AUTOSAR XML (schema 4-0-3)
package /ComponentTypes
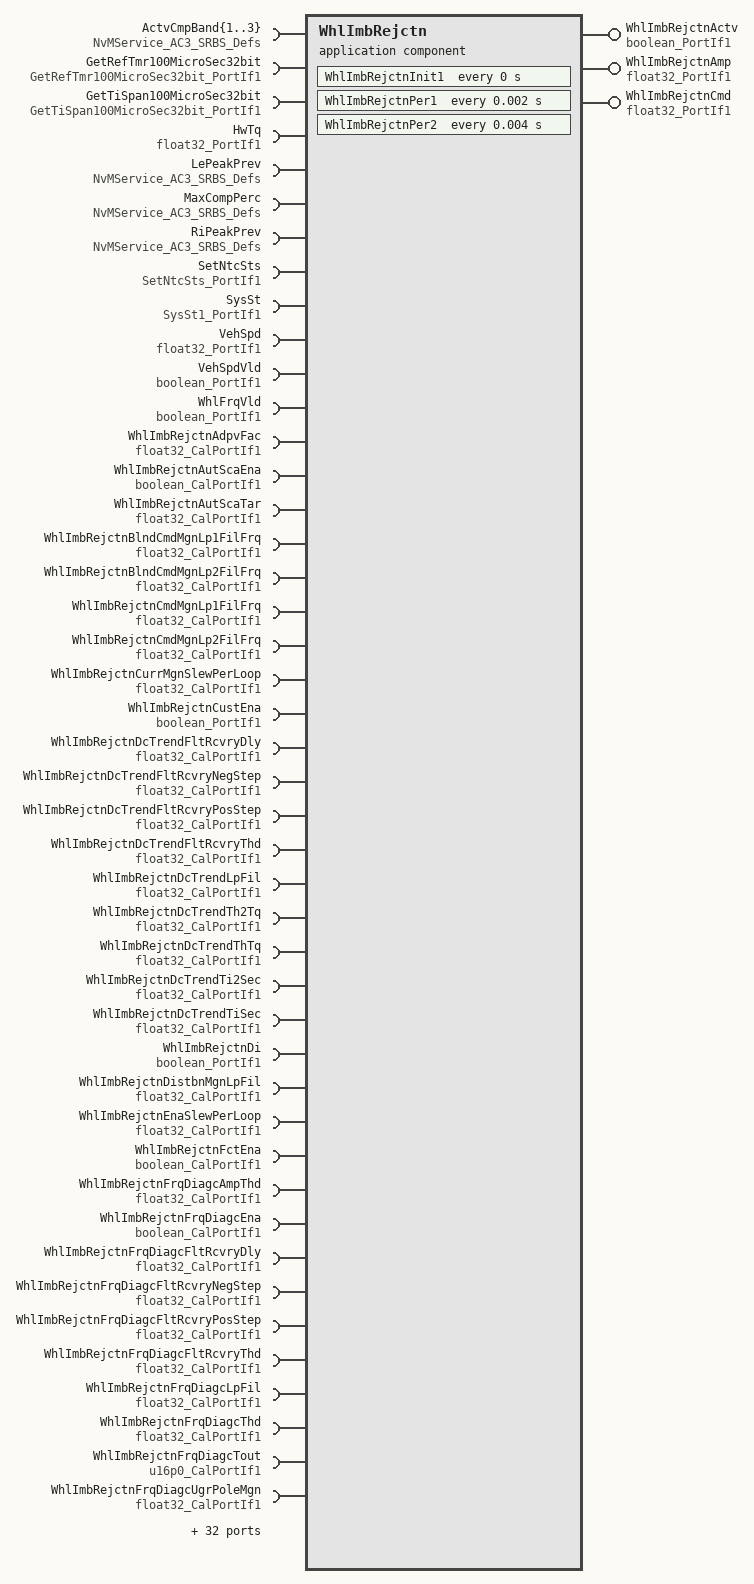
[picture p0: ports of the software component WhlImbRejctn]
  application sw component type WhlImbRejctn
    provide port WhlImbRejctnActv: nonqueued-sender-com-spec{data-element=Logl, init-value=0}, provided-interface=boolean_PortIf1
    provide port WhlImbRejctnAmp: nonqueued-sender-com-spec{data-element=Val, init-value=0}, provided-interface=float32_PortIf1
    provide port WhlImbRejctnCmd: nonqueued-sender-com-spec{data-element=Val, init-value=0}, provided-interface=float32_PortIf1
    78 x require port:
      ActvCmpBand{1..3}: required-interface=NvMService_AC3_SRBS_Defs
      GetRefTmr100MicroSec32bit: required-interface=GetRefTmr100MicroSec32bit_PortIf1
      GetTiSpan100MicroSec32bit: required-interface=GetTiSpan100MicroSec32bit_PortIf1
      HwTq: nonqueued-receiver-com-spec{data-element=Val, filter=data-filter-type=ALWAYS, init-value=0}, required-interface=float32_PortIf1
      LePeakPrev: required-interface=NvMService_AC3_SRBS_Defs
      MaxCompPerc: required-interface=NvMService_AC3_SRBS_Defs
      RiPeakPrev: required-interface=NvMService_AC3_SRBS_Defs
      SetNtcSts: required-interface=SetNtcSts_PortIf1
      SysSt: nonqueued-receiver-com-spec{data-element=Val, filter=data-filter-type=ALWAYS, init-value=3}, required-interface=SysSt1_PortIf1
      VehSpd: nonqueued-receiver-com-spec{data-element=Val, filter=data-filter-type=ALWAYS, init-value=0}, required-interface=float32_PortIf1
      VehSpdVld: nonqueued-receiver-com-spec{data-element=Logl, filter=data-filter-type=ALWAYS, init-value=1}, required-interface=boolean_PortIf1
      WhlFrqVld: nonqueued-receiver-com-spec{data-element=Logl, filter=data-filter-type=ALWAYS, init-value=0}, required-interface=boolean_PortIf1
      WhlImbRejctnAdpvFac: parameter-require-com-spec{init-value=0.199997, parameter=Val}, required-interface=float32_CalPortIf1
      WhlImbRejctnAutScaEna: parameter-require-com-spec{init-value=1, parameter=Logl}, required-interface=boolean_CalPortIf1
      WhlImbRejctnAutScaTar: parameter-require-com-spec{init-value=0.199219, parameter=Val}, required-interface=float32_CalPortIf1
      WhlImbRejctnBlndCmdMgnLp1FilFrq: parameter-require-com-spec{init-value=5, parameter=Val}, required-interface=float32_CalPortIf1
      WhlImbRejctnBlndCmdMgnLp2FilFrq: parameter-require-com-spec{init-value=5, parameter=Val}, required-interface=float32_CalPortIf1
      WhlImbRejctnCmdMgnLp1FilFrq: parameter-require-com-spec{init-value=5, parameter=Val}, required-interface=float32_CalPortIf1
      WhlImbRejctnCmdMgnLp2FilFrq: parameter-require-com-spec{init-value=5, parameter=Val}, required-interface=float32_CalPortIf1
      WhlImbRejctnCurrMgnSlewPerLoop: parameter-require-com-spec{init-value=0.002, parameter=Val}, required-interface=float32_CalPortIf1
      WhlImbRejctnCustEna: nonqueued-receiver-com-spec{data-element=Logl, filter=data-filter-type=ALWAYS, init-value=1}, required-interface=boolean_PortIf1
      WhlImbRejctnDcTrendFltRcvryDly: parameter-require-com-spec{init-value=5, parameter=Val}, required-interface=float32_CalPortIf1
      WhlImbRejctnDcTrendFltRcvryNegStep: parameter-require-com-spec{init-value=10, parameter=Val}, required-interface=float32_CalPortIf1
      WhlImbRejctnDcTrendFltRcvryPosStep: parameter-require-com-spec{init-value=10, parameter=Val}, required-interface=float32_CalPortIf1
      WhlImbRejctnDcTrendFltRcvryThd: parameter-require-com-spec{init-value=100, parameter=Val}, required-interface=float32_CalPortIf1
      WhlImbRejctnDcTrendLpFil: parameter-require-com-spec{init-value=0.2, parameter=Val}, required-interface=float32_CalPortIf1
      WhlImbRejctnDcTrendTh2Tq: parameter-require-com-spec{init-value=0.1, parameter=Val}, required-interface=float32_CalPortIf1
      WhlImbRejctnDcTrendThTq: parameter-require-com-spec{init-value=0.05, parameter=Val}, required-interface=float32_CalPortIf1
      WhlImbRejctnDcTrendTi2Sec: parameter-require-com-spec{init-value=0.014, parameter=Val}, required-interface=float32_CalPortIf1
      WhlImbRejctnDcTrendTiSec: parameter-require-com-spec{init-value=0.125, parameter=Val}, required-interface=float32_CalPortIf1
      WhlImbRejctnDi: nonqueued-receiver-com-spec{data-element=Logl, filter=data-filter-type=ALWAYS, init-value=0}, required-interface=boolean_PortIf1
      WhlImbRejctnDistbnMgnLpFil: parameter-require-com-spec{init-value=0.5, parameter=Val}, required-interface=float32_CalPortIf1
      WhlImbRejctnEnaSlewPerLoop: parameter-require-com-spec{init-value=0.01, parameter=Val}, required-interface=float32_CalPortIf1
      WhlImbRejctnFctEna: parameter-require-com-spec{init-value=1, parameter=Logl}, required-interface=boolean_CalPortIf1
      WhlImbRejctnFrqDiagcAmpThd: parameter-require-com-spec{init-value=0.0507813, parameter=Val}, required-interface=float32_CalPortIf1
      WhlImbRejctnFrqDiagcEna: parameter-require-com-spec{init-value=1, parameter=Logl}, required-interface=boolean_CalPortIf1
      WhlImbRejctnFrqDiagcFltRcvryDly: parameter-require-com-spec{init-value=5, parameter=Val}, required-interface=float32_CalPortIf1
      WhlImbRejctnFrqDiagcFltRcvryNegStep: parameter-require-com-spec{init-value=10, parameter=Val}, required-interface=float32_CalPortIf1
      WhlImbRejctnFrqDiagcFltRcvryPosStep: parameter-require-com-spec{init-value=10, parameter=Val}, required-interface=float32_CalPortIf1
      WhlImbRejctnFrqDiagcFltRcvryThd: parameter-require-com-spec{init-value=100, parameter=Val}, required-interface=float32_CalPortIf1
      WhlImbRejctnFrqDiagcLpFil: parameter-require-com-spec{init-value=2, parameter=Val}, required-interface=float32_CalPortIf1
      WhlImbRejctnFrqDiagcThd: parameter-require-com-spec{init-value=0.0117188, parameter=Val}, required-interface=float32_CalPortIf1
      WhlImbRejctnFrqDiagcTout: parameter-require-com-spec{init-value=500, parameter=Val}, required-interface=u16p0_CalPortIf1
      WhlImbRejctnFrqDiagcUgrPoleMgn: parameter-require-com-spec{init-value=0.949997, parameter=Val}, required-interface=float32_CalPortIf1
      WhlImbRejctnFrqScaTblX: parameter-require-com-spec{init-value=[8192, 9216, 10240, 23552, 24576, 25600], parameter=Ary1D}, required-interface=Ary1D_u6p10_6_CalPortIf1
      WhlImbRejctnFrqScaTblY: parameter-require-com-spec{init-value=[0, 16384, 32768, 32768, 16384, 0], parameter=Ary1D}, required-interface=Ary1D_u1p15_6_CalPortIf1
      WhlImbRejctnMaxDurn: parameter-require-com-spec{init-value=8000, parameter=Val}, required-interface=uint16_CalPortIf1
      WhlImbRejctnMaxMgn: parameter-require-com-spec{init-value=0.2, parameter=Val}, required-interface=float32_CalPortIf1
      WhlImbRejctnMaxMgnFltNegStep: parameter-require-com-spec{init-value=10, parameter=Val}, required-interface=float32_CalPortIf1
      WhlImbRejctnMaxMgnFltPosStep: parameter-require-com-spec{init-value=10, parameter=Val}, required-interface=float32_CalPortIf1
      WhlImbRejctnMaxMgnFltRcvryDly: parameter-require-com-spec{init-value=5, parameter=Val}, required-interface=float32_CalPortIf1
      WhlImbRejctnMaxMgnFltRcvryNegStep: parameter-require-com-spec{init-value=10, parameter=Val}, required-interface=float32_CalPortIf1
      WhlImbRejctnMaxMgnFltRcvryPosStep: parameter-require-com-spec{init-value=10, parameter=Val}, required-interface=float32_CalPortIf1
      WhlImbRejctnMaxMgnFltRcvryThd: parameter-require-com-spec{init-value=100, parameter=Val}, required-interface=float32_CalPortIf1
      WhlImbRejctnMaxMgnFltThd: parameter-require-com-spec{init-value=100, parameter=Val}, required-interface=float32_CalPortIf1
      WhlImbRejctnMgnEstimnDeltaSca: parameter-require-com-spec{init-value=0.0005, parameter=Val}, required-interface=float32_CalPortIf1
      WhlImbRejctnMgnEstimnDiThd: parameter-require-com-spec{init-value=0.209, parameter=Val}, required-interface=float32_CalPortIf1
      WhlImbRejctnMgnEstimnEnaThd: parameter-require-com-spec{init-value=0.21, parameter=Val}, required-interface=float32_CalPortIf1
      WhlImbRejctnMgnEstimnFrq: parameter-require-com-spec{init-value=14, parameter=Val}, required-interface=float32_CalPortIf1
      WhlImbRejctnMgnEstimnFrqDelta: parameter-require-com-spec{init-value=4, parameter=Val}, required-interface=float32_CalPortIf1
      WhlImbRejctnMgnEstimnLeak: parameter-require-com-spec{init-value=1, parameter=Val}, required-interface=float32_CalPortIf1
      WhlImbRejctnPhaAdjX: parameter-require-com-spec{init-value=[5120, 10240, 15360], parameter=Ary1D}, required-interface=Ary1D_u7p9_3_CalPortIf1
      WhlImbRejctnPhaAdjY: parameter-require-com-spec{init-value=[17280, 15360, 15360], parameter=Ary1D}, required-interface=Ary1D_s8p7_3_CalPortIf1
      WhlImbRejctnRampDwnTi: parameter-require-com-spec{init-value=2000, parameter=Val}, required-interface=u16p0_CalPortIf1
      WhlImbRejctnScaCncl: parameter-require-com-spec{init-value=0.1, parameter=Val}, required-interface=float32_CalPortIf1
      WhlImbRejctnUgrPoleMgn: parameter-require-com-spec{init-value=1, parameter=Val}, required-interface=float32_CalPortIf1
      WhlImbRejctnVehSpdEna: parameter-require-com-spec{init-value=0, parameter=Val}, required-interface=float32_CalPortIf1
      WhlImbRejctnWhlSpdCorrlnFltRcvryDly: parameter-require-com-spec{init-value=5, parameter=Val}, required-interface=float32_CalPortIf1
      WhlImbRejctnWhlSpdCorrlnFltRcvryNegStep: parameter-require-com-spec{init-value=10, parameter=Val}, required-interface=float32_CalPortIf1
      WhlImbRejctnWhlSpdCorrlnFltRcvryPosStep: parameter-require-com-spec{init-value=10, parameter=Val}, required-interface=float32_CalPortIf1
      WhlImbRejctnWhlSpdCorrlnFltRcvryThd: parameter-require-com-spec{init-value=100, parameter=Val}, required-interface=float32_CalPortIf1
      WhlImbRejctnWhlSpdCorrlnThd: parameter-require-com-spec{init-value=90, parameter=Val}, required-interface=float32_CalPortIf1
      WhlImbRejctnWhlSpdCorrlnTi: parameter-require-com-spec{init-value=500, parameter=Val}, required-interface=u16p0_CalPortIf1
      WhlImbRejctnWhlSpdLpFil: parameter-require-com-spec{init-value=3, parameter=Val}, required-interface=float32_CalPortIf1
      WhlLeFrq: nonqueued-receiver-com-spec{data-element=Val, filter=data-filter-type=ALWAYS, init-value=0.01}, required-interface=float32_PortIf1
      WhlRiFrq: nonqueued-receiver-com-spec{data-element=Val, filter=data-filter-type=ALWAYS, init-value=0.01}, required-interface=float32_PortIf1
    behavior WhlImbRejctn_InternalBehavior
      ar-typed-per-instance-memorys:
        77 x data, all with sw-calibration-access=READ-ONLY:
          ActvCmpBand{1..3}: type=uint32
          BlndCmdMgnLp1Fil: type=FilLpRec1
          BlndCmdMgnLp2Fil: type=FilLpRec1
          CmdMgnLp1Fil: type=FilLpRec1
          CmdMgnLp2Fil: type=FilLpRec1
          DcTrendFltRcvry: type=PassFailCntrDiagcRec1
          DcTrendLpFil: type=FilLpRec1
          DcTrendLrngEnaPrev: type=boolean
          DcTrendLrngEnaPrevTmr1: type=boolean
          DcTrendLrngEnaPrevTmr2: type=boolean
          DcTrendRefTiEnaLrng: type=uint32
          DcTrendRefTiEnaLrngTmr1: type=uint32
          DcTrendRefTiEnaLrngTmr2: type=uint32
          DistbnMagEnadPrev: type=boolean
          DistbnMgnLeLpFil: type=FilLpRec1
          DistbnMgnRiLpFil: type=FilLpRec1
          DlyIdxLe: type=uint8
          DlyIdxRi: type=uint8
          dWhlImbRejctnCnclTqOutp: type=float32
          dWhlImbRejctnCurrMgnLe: type=float32
          dWhlImbRejctnCurrMgnRi: type=float32
          dWhlImbRejctnFildWhlSpdLe: type=float32
          dWhlImbRejctnFildWhlSpdRi: type=float32
          dWhlImbRejctnLMSqdOutLe: type=float32
          dWhlImbRejctnLMSqdOutRi: type=float32
          dWhlImbRejctnScaLe: type=float32
          dWhlImbRejctnScaRi: type=float32
          dWhlImbRejctnWhlSpdCorrPerc: type=float32
          EnaSlewPerLoop: type=float32
          FrqDiagcFltRcvry: type=PassFailCntrDiagcRec1
          FrqDiagcLpFil: type=FilLpRec1
          FrqDiagcLrngEnaPrev: type=boolean
          FrqDiagcLrngEnaPrevTiOut: type=boolean
          FrqDiagcRefTiEnaLrng: type=uint32
          FrqDiagcRefTiEnaLrngTiOut: type=uint32
          FrqDiagcUgr1: type=float32
          FrqDiagcUgr2: type=float32
          LeCurrMgnSlewPerLoop: type=float32
          LePeakPrev: type=float32
          LeStDlyUpd: type=Ary1D_f32_30
          LeStVariUpd: type=Ary1D_f32_30
          MaxCompPerc: type=float32
          MaxMgnFltRcvry: type=PassFailCntrDiagcRec1
          MaxMgnLrngEnaPrev: type=boolean
          MaxMgnRefTiEnaLrng: type=uint32
          PhaAdjFil1Coeff1: type=float32
          PhaAdjFil1Coeff2: type=float32
          PhaAdjFil2Coeff1: type=float32
          PhaAdjFil2Coeff2: type=float32
          PrevFlt: type=float32
          PrevHwTq: type=float32
          PrevSts: type=boolean
          RampNo: type=boolean
          RampYes: type=boolean
          RiCurrMgnSlewPerLoop: type=float32
          RiPeakPrev: type=float32
          RiStDlyUpd: type=Ary1D_f32_30
          RiStVariUpd: type=Ary1D_f32_30
          ScaLe: type=float32
          ScaRi: type=float32
          SlowSpdDiagcLrngEnaPrevTmr: type=boolean
          SlowSpdDiagcRefTiEnaLrngTmr: type=uint32
          StordValLe: type=Ary1D_f32_30
          StordValRi: type=Ary1D_f32_30
          UgrLe1: type=float32
          UgrLe2: type=float32
          UgrRi1: type=float32
          UgrRi2: type=float32
          WhlSpdCorrlnDiagcLrngEnaPrev: type=boolean
          WhlSpdCorrlnDiagcRefTiEnaLrng: type=uint32
          WhlSpdCorrlnFltRcvry: type=PassFailCntrDiagcRec1
          WhlSpdCorrlnLrngEnaPrevTmr: type=boolean
          WhlSpdCorrlnRefTiEnaLrngTmr: type=uint32
          WhlSpdLeLpFil: type=FilLpRec1
          WhlSpdRiLpFil: type=FilLpRec1
      timing event WhlImbRejctnInit1_InitEvent: start-on-event=WhlImbRejctnInit1, period=0
      timing event TMT_WhlImbRejctnPer1: start-on-event=WhlImbRejctnPer1, period=0.002
      timing event TMT_WhlImbRejctnPer2: start-on-event=WhlImbRejctnPer2, period=0.004
      explicit-inter-runnable-variables:
        9 x data, all with init-value=0:
          CmdAmp: type=float32
          CurrMgnSlewRate: type=float32
          DcTrendFlt: type=boolean
          EnaSlewRate: type=float32
          FrqDiagcFlt: type=boolean
          IniCmpFlt: type=boolean
          MaxMgnFlt: type=boolean
          SlowSpdDiagc: type=boolean
          WhlSpdCorrlnFlt: type=boolean
      runnable WhlImbRejctnInit1
        12 x sync call, all with timeout=0:
          SC_ActvCmpBand1_GetErrorStatus: operation=ActvCmpBand1.GetErrorStatus
          SC_ActvCmpBand1_SetRamBlockStatus: operation=ActvCmpBand1.SetRamBlockStatus
          SC_ActvCmpBand2_GetErrorStatus: operation=ActvCmpBand2.GetErrorStatus
          SC_ActvCmpBand2_SetRamBlockStatus: operation=ActvCmpBand2.SetRamBlockStatus
          SC_ActvCmpBand3_GetErrorStatus: operation=ActvCmpBand3.GetErrorStatus
          SC_ActvCmpBand3_SetRamBlockStatus: operation=ActvCmpBand3.SetRamBlockStatus
          SC_LePeakPrev_GetErrorStatus: operation=LePeakPrev.GetErrorStatus
          SC_LePeakPrev_SetRamBlockStatus: operation=LePeakPrev.SetRamBlockStatus
          SC_MaxCompPerc_GetErrorStatus: operation=MaxCompPerc.GetErrorStatus
          SC_MaxCompPerc_SetRamBlockStatus: operation=MaxCompPerc.SetRamBlockStatus
          SC_RiPeakPrev_GetErrorStatus: operation=RiPeakPrev.GetErrorStatus
          SC_RiPeakPrev_SetRamBlockStatus: operation=RiPeakPrev.SetRamBlockStatus
        written-local-variables:
          access WRITE_CurrMgnSlewRate: accessed-variable=CurrMgnSlewRate
          access WRITE_EnaSlewRate: accessed-variable=EnaSlewRate
          access WRITE_IniCmpFlt: accessed-variable=IniCmpFlt
      runnable WhlImbRejctnPer1
        data-receive-point-by-arguments:
          9 x access:
            REC_DiagcStsWhlImbRejctnDi_Logl: accessed-variable=WhlImbRejctnDi.Logl
            REC_HwTq_Val: accessed-variable=HwTq.Val
            REC_SysSt_Val: accessed-variable=SysSt.Val
            REC_VehSpd_Val: accessed-variable=VehSpd.Val
            REC_VehSpdVld_Logl: accessed-variable=VehSpdVld.Logl
            REC_WhlFrqSts_Logl: accessed-variable=WhlFrqVld.Logl
            REC_WhlImbRejctnCustEna_Logl: accessed-variable=WhlImbRejctnCustEna.Logl
            REC_WhlLeFrqQlfd_Val: accessed-variable=WhlLeFrq.Val
            REC_WhlRiFrqQlfd_Val: accessed-variable=WhlRiFrq.Val
        data-send-points:
          access SEND_WhlImbRejctnActv_Logl: accessed-variable=WhlImbRejctnActv.Logl
          access SEND_WhlImbRejctnAmp_Val: accessed-variable=WhlImbRejctnAmp.Val
          access SEND_WhlImbRejctnCmd_Val: accessed-variable=WhlImbRejctnCmd.Val
        read-local-variables:
          4 x access:
            READ_CurrMgnSlewRate: accessed-variable=CurrMgnSlewRate
            READ_EnaSlewRate: accessed-variable=EnaSlewRate
            READ_IniCmpFlt: accessed-variable=IniCmpFlt
            READ_SlowSpdDiagc: accessed-variable=SlowSpdDiagc
        sync call SC_GetRefTmr100MicroSec32bit_Oper: operation=GetRefTmr100MicroSec32bit.Oper, timeout=0
        sync call SC_GetTiSpan100MicroSec32bit_Oper: operation=GetTiSpan100MicroSec32bit.Oper, timeout=0
        sync call SC_SetNtcSts_Oper: operation=SetNtcSts.Oper, timeout=0
        written-local-variables:
          5 x access:
            WRITE_CmdAmp: accessed-variable=CmdAmp
            WRITE_DcTrendFlt: accessed-variable=DcTrendFlt
            WRITE_FrqDiagcFlt: accessed-variable=FrqDiagcFlt
            WRITE_MaxMgnFlt: accessed-variable=MaxMgnFlt
            WRITE_WhlSpdCorrlnFlt: accessed-variable=WhlSpdCorrlnFlt
      runnable WhlImbRejctnPer2
        read-local-variables:
          5 x access:
            READ_CmdAmp: accessed-variable=CmdAmp
            READ_DcTrendFlt: accessed-variable=DcTrendFlt
            READ_FrqDiagcFlt: accessed-variable=FrqDiagcFlt
            READ_MaxMgnFlt: accessed-variable=MaxMgnFlt
            READ_WhlSpdCorrlnFlt: accessed-variable=WhlSpdCorrlnFlt
        sync call SC_GetRefTmr100MicroSec32bit_Oper: operation=GetRefTmr100MicroSec32bit.Oper, timeout=0
        sync call SC_GetTiSpan100MicroSec32bit_Oper: operation=GetTiSpan100MicroSec32bit.Oper, timeout=0
        written-local-variables:
          access WRITE_SlowSpdDiagc: accessed-variable=SlowSpdDiagc
      6 x swc service dependency:
        NvMActvCmpBand2
          assigned-datas:
            role=ramBlock, used-data-element=ActvCmpBand2
            role=defaultValue, used-parameter-element=ActvCmpBand2Dft
          assigned-ports:
            port-prototype=ActvCmpBand2, role=NvMService_AC3_SRBS_Defs
            port-prototype=ActvCmpBand2, role=NvMService_AC3_SRBS_Defs
          service-needs:
            nv block needs NvMActvCmpBand2: n-data-sets=0, readonly=false, reliability=ERROR-DETECTION, resistant-to-changed-sw=true, restore-at-start=true, store-at-shutdown=true, write-only-once=false, writing-frequency=0, writing-priority=LOW
        NvMLePeakPrev
          assigned-datas:
            role=ramBlock, used-data-element=LePeakPrev
            role=defaultValue, used-parameter-element=LePeakPrevDft
          assigned-ports:
            port-prototype=LePeakPrev, role=NvMService_AC3_SRBS_Defs
            port-prototype=LePeakPrev, role=NvMService_AC3_SRBS_Defs
          service-needs:
            nv block needs NvMLePeakPrev: n-data-sets=0, readonly=false, reliability=ERROR-DETECTION, resistant-to-changed-sw=true, restore-at-start=true, store-at-shutdown=true, write-only-once=false, writing-frequency=0, writing-priority=LOW
        NvMMaxCompPerc
          assigned-datas:
            role=ramBlock, used-data-element=MaxCompPerc
            role=defaultValue, used-parameter-element=MaxCompPercDft
          assigned-ports:
            port-prototype=MaxCompPerc, role=NvMService_AC3_SRBS_Defs
            port-prototype=MaxCompPerc, role=NvMService_AC3_SRBS_Defs
          service-needs:
            nv block needs NvmRiPeakPrev: n-data-sets=0, readonly=false, reliability=ERROR-DETECTION, resistant-to-changed-sw=true, restore-at-start=true, store-at-shutdown=true, write-only-once=false, writing-frequency=0, writing-priority=LOW
        NvMRiPeakPrev
          assigned-datas:
            role=ramBlock, used-data-element=RiPeakPrev
            role=defaultValue, used-parameter-element=RiPeakPrevDft
          assigned-ports:
            port-prototype=RiPeakPrev, role=NvMService_AC3_SRBS_Defs
            port-prototype=RiPeakPrev, role=NvMService_AC3_SRBS_Defs
          service-needs:
            nv block needs NvMRiPeakPrev: n-data-sets=0, readonly=false, reliability=ERROR-DETECTION, resistant-to-changed-sw=true, restore-at-start=true, store-at-shutdown=true, write-only-once=false, writing-frequency=0, writing-priority=LOW
        NvmActvCmpBand1
          assigned-datas:
            role=ramBlock, used-data-element=ActvCmpBand1
            role=defaultValue, used-parameter-element=ActvCmpBand1Dft
          assigned-ports:
            port-prototype=ActvCmpBand1, role=NvMService_AC3_SRBS_Defs
            port-prototype=ActvCmpBand1, role=NvMService_AC3_SRBS_Defs
          service-needs:
            nv block needs NvmActvCmpBand1: n-data-sets=0, readonly=false, reliability=ERROR-DETECTION, resistant-to-changed-sw=true, restore-at-start=true, store-at-shutdown=true, write-only-once=false, writing-frequency=0, writing-priority=LOW
        NvmActvCmpBand3
          assigned-datas:
            role=ramBlock, used-data-element=ActvCmpBand3
            role=defaultValue, used-parameter-element=ActvCmpBand3Dft
          assigned-ports:
            port-prototype=ActvCmpBand3, role=NvMService_AC3_SRBS_Defs
            port-prototype=ActvCmpBand3, role=NvMService_AC3_SRBS_Defs
          service-needs:
            nv block needs NvmActvCmpBand3: n-data-sets=0, readonly=false, reliability=ERROR-DETECTION, resistant-to-changed-sw=true, restore-at-start=true, store-at-shutdown=true, write-only-once=false, writing-frequency=0, writing-priority=LOW
      shared-parameters:
        6 x parameter data prototype, all with sw-calibration-access=READ-WRITE, init-value=0:
          ActvCmpBand{1..3}Dft: type=uint32
          LePeakPrevDft: type=float32
          MaxCompPercDft: type=float32
          RiPeakPrevDft: type=float32
  swc implementation WhlImbRejctn_Implementation: behavior=WhlImbRejctn_InternalBehavior
    code-descriptors:
      code Default: artifact-descriptors=autosar-engineering-object={short-label=Default, category=SWSRC}
